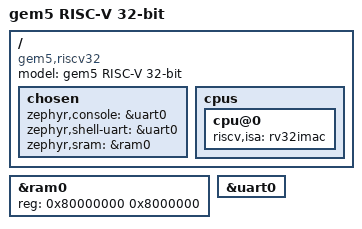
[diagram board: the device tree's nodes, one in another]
/* SPDX-License-Identifier: Apache-2.0 */

/dts-v1/;

#include <qemu/virt-riscv32.dtsi>

/ {
	model = "gem5 RISC-V 32-bit";
	compatible = "gem5,riscv32";

	chosen {
		zephyr,console = &uart0;
		zephyr,shell-uart = &uart0;
		zephyr,sram = &ram0;
	};

	cpus {
		cpu@0 {
			riscv,isa = "rv32imac";
		};
	};
};

/* Override memory size to 128MB for gem5 */
&ram0 {
	reg = <0x80000000 0x8000000>;
};

&uart0 {
	status = "okay";
};
